# MCP9808 register map
Vendor: Google Inc.; File version: 0.1.0
This is a test description
Registers are 16-bit, read-write, reset 0x0 unless marked. A register's access mark holds for its fields unless they carry their own. Offsets are from the block's base; lines under a group give offsets from that group; [hi:lo] are bit positions; {n}, {i} and the like mark numbered series; 'fields as' and 'values as' point back to an identical list; <NAME> marks a mode.

## Memory map
0x00000018 MCP9808 size 0x78 — This is a test description

## MCP9808 — This is a test description
Base 0x00000018
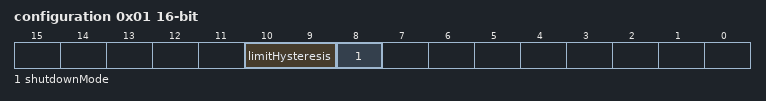
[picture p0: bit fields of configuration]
0x01 configuration (reset mask 0xFF) — The MCP9808 has a 16-bit Configuration register (CONFIG) that allows the user to set various functions for a robust temperature monitoring system. Bits 10 through 0 are used to select the temperature alert output hysteresis, device shutdown or Low-Power mode, temperature boundary and critical temperature lock, and temperature Alert output enable/disable. In addition, Alert output condition (output set for TUPPER and TLOWER temperature boundary or TCRIT only), Alert output status and Alert output polarity and mode (Comparator Output or Interrupt Output mode) are user-configurable.
  [10:9] limitHysteresis ro range 9..10 — This bit can not be altered when either of the Lock bits are set (bit 6 and bit 7). This bit can be programmed in Shutdown mode.
    0=Temp_0C (0°C (power-up default)); 1=Temp_1C5 (+1.5°C); 2=Temp_3C (+3.0°C); 3=Temp_6C (+6.0°C)
  [8] shutdownMode ro range 8..8 — In shutdown, all power-consuming activities are disabled, though all registers can be written to or read. This bit cannot be set to ‘1’ when either of the Lock bits is set (bit 6 and bit 7). However, it can be cleared to ‘0’ for continuous conversion while locked.
    0=continousConversion (Continuous conversion (power-up default)); 1=Shutdown (Low-Power mode)

## Licence text in the file
Copyright (C) 2019 Google Inc. Licensed under the Apache License, Version 2.0 (the "License"); you may not use this file except in compliance with the License. You may obtain a copy of the License at http://www.apache.org/licenses/LICENSE-2.0 Unless required by applicable law or agreed to in writing, software distributed under the License is distributed on an "AS IS" BASIS, WITHOUT WARRANTIES OR CONDITIONS OF ANY KIND, either express or implied. See the License for the specific language governing permissions and limitations under the License.
